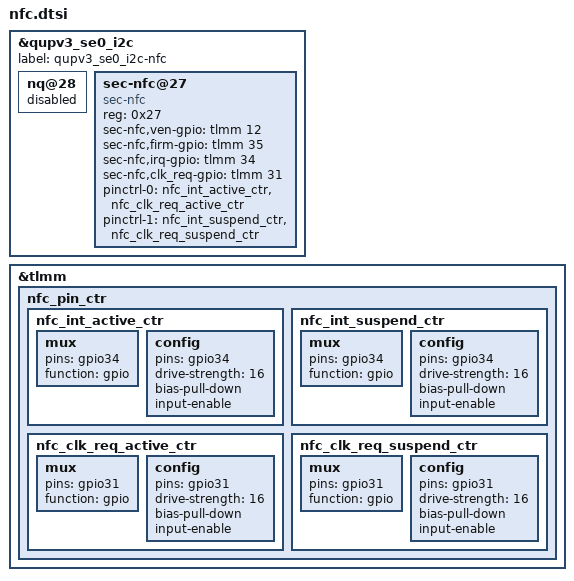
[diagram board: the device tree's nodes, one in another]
&qupv3_se0_i2c {
    nq@28{
        status = "disabled";  /*disable qcom default nfc*/
    };
};
&qupv3_se0_i2c {
	/* On Low speed expansion */
	label = "qupv3_se0_i2c-nfc";
	status = "okay";
	sec-nfc@27 {
		compatible = "sec-nfc";
		reg = <0x27>;
		sec-nfc,ven-gpio = <&tlmm 12 0>;/*nfc shutdown*/
		sec-nfc,firm-gpio = <&tlmm 35 0>;/*irq to nfc*/
		sec-nfc,irq-gpio = <&tlmm 34 0x2008>;/*irq to cpu*/
		sec-nfc,clk_req-gpio = <&tlmm 31 0>;/*clock req to cpu*/
        pinctrl-names = "sec_nfc_active", "sec_nfc_suspend";
        pinctrl-0 = <&nfc_int_active_ctr &nfc_clk_req_active_ctr>;
		pinctrl-1 = <&nfc_int_suspend_ctr &nfc_clk_req_suspend_ctr>;
	};
};
&tlmm {
     nfc_pin_ctr{
         nfc_int_active_ctr: nfc_int_active_ctr {
                mux {
                        pins = "gpio34";
                        function = "gpio";
                };

                config {
                        pins = "gpio34";
                        drive-strength = <16>;
                        bias-pull-down;
                        input-enable;
                };

        };
	nfc_int_suspend_ctr: nfc_int_suspend_ctr {
                mux {
                        pins = "gpio34";
                        function = "gpio";
                };

                config {
                        pins = "gpio34";
                        drive-strength = <16>;
                        bias-pull-down;
                        input-enable;
                };

        };
	nfc_clk_req_active_ctr: nfc_clk_req_active_ctr {
                mux {
                        pins = "gpio31";
                        function = "gpio";
                };

                config {
                        pins = "gpio31";
                        drive-strength = <16>;
                        bias-pull-down;
                        input-enable;
                };

        };
	nfc_clk_req_suspend_ctr: nfc_clk_req_suspend_ctr {
                mux {
                        pins = "gpio31";
                        function = "gpio";
                };

                config {
                        pins = "gpio31";
                        drive-strength = <16>;
                        bias-pull-down;
                        input-enable;
                };

        };
    };
};  
